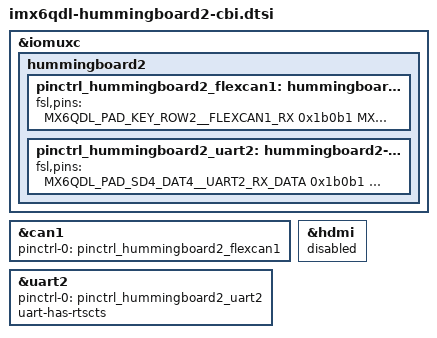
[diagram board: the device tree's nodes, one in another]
/*
 * Device Tree file for SolidRun HummingBoard2
 * Copyright (C) 2022 Josua Mayer <josua@solid-run.com>
 * Based on dt work by Baruch Siach
 *
 * This file is dual-licensed: you can use it either under the terms
 * of the GPL or the X11 license, at your option. Note that this dual
 * licensing only applies to this file, and not this project as a
 * whole.
 *
 *  a) This file is free software; you can redistribute it and/or
 *     modify it under the terms of the GNU General Public License as
 *     published by the Free Software Foundation; either version 2 of the
 *     License.
 *
 *     This file is distributed in the hope that it will be useful,
 *     but WITHOUT ANY WARRANTY; without even the implied warranty of
 *     MERCHANTABILITY or FITNESS FOR A PARTICULAR PURPOSE.  See the
 *     GNU General Public License for more details.
 *
 * Or, alternatively,
 *
 *  b) Permission is hereby granted, free of charge, to any person
 *     obtaining a copy of this software and associated documentation
 *     files (the "Software"), to deal in the Software without
 *     restriction, including without limitation the rights to use
 *     copy, modify, merge, publish, distribute, sublicense, and/or
 *     sell copies of the Software, and to permit persons to whom the
 *     Software is furnished to do so, subject to the following
 *     conditions:
 *
 *     The above copyright notice and this permission notice shall be
 *     included in all copies or substantial portions of the Software.
 *
 *     THE SOFTWARE IS PROVIDED "AS IS", WITHOUT WARRANTY OF ANY KIND,
 *     EXPRESS OR IMPLIED, INCLUDING BUT NOT LIMITED TO THE WARRANTIES
 *     OF MERCHANTABILITY, FITNESS FOR A PARTICULAR PURPOSE AND
 *     NONINFRINGEMENT. IN NO EVENT SHALL THE AUTHORS OR COPYRIGHT
 *     HOLDERS BE LIABLE FOR ANY CLAIM, DAMAGES OR OTHER LIABILITY,
 *     WHETHER IN AN ACTION OF CONTRACT, TORT OR OTHERWISE, ARISING
 *     FROM, OUT OF OR IN CONNECTION WITH THE SOFTWARE OR THE USE OR
 *     OTHER DEALINGS IN THE SOFTWARE.
 */

&iomuxc {
	hummingboard2 {
		pinctrl_hummingboard2_flexcan1: hummingboard2-flexcan1 {
			fsl,pins = <
				MX6QDL_PAD_KEY_ROW2__FLEXCAN1_RX	0x1b0b1
				MX6QDL_PAD_KEY_COL2__FLEXCAN1_TX	0x1b0b1
			>;
		};

		pinctrl_hummingboard2_uart2: hummingboard2-uart2 {
			fsl,pins = <
				MX6QDL_PAD_SD4_DAT4__UART2_RX_DATA	0x1b0b1
				MX6QDL_PAD_SD4_DAT7__UART2_TX_DATA	0x1b0b1
				MX6QDL_PAD_SD4_DAT6__UART2_CTS_B	0x1b0b1
			>;
		};
	};
};

&can1 {
	pinctrl-names = "default";
	pinctrl-0 = <&pinctrl_hummingboard2_flexcan1>;
	status = "okay";
};

&hdmi {
	status = "disabled";
};

&uart2 {
	pinctrl-names = "default";
	pinctrl-0 = <&pinctrl_hummingboard2_uart2>;
	uart-has-rtscts;
	status = "okay";
};
